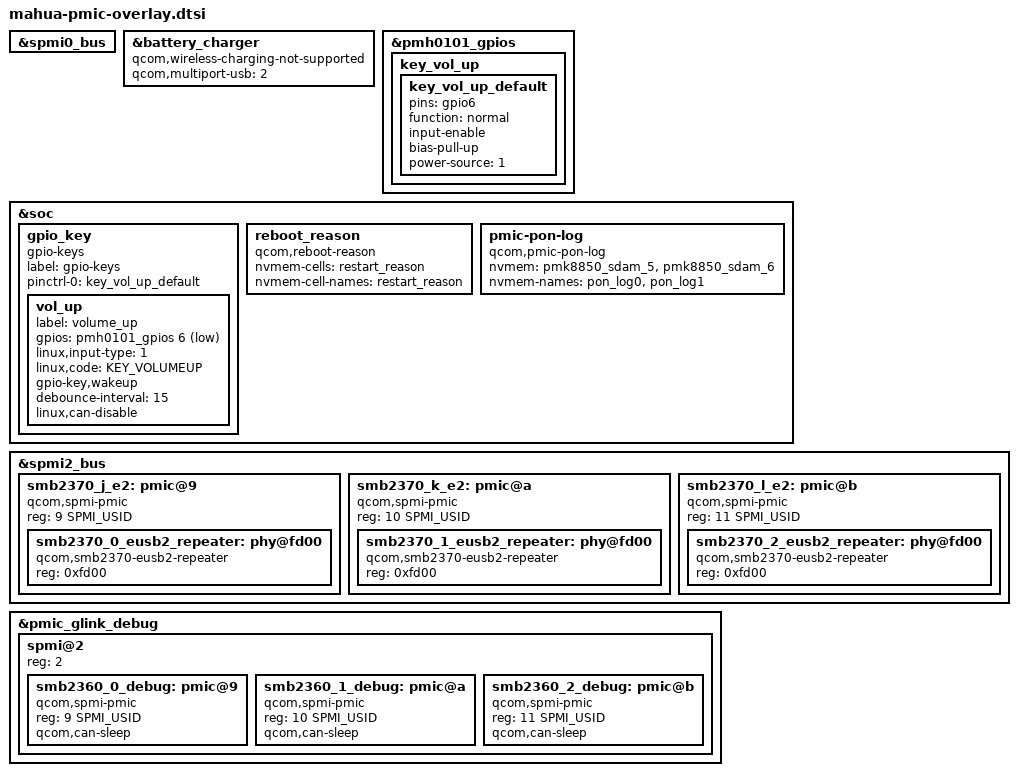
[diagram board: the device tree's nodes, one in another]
// SPDX-License-Identifier: BSD-3-Clause
/*
 * Copyright (c) Qualcomm Technologies, Inc. and/or its subsidiaries.
 */

#include <dt-bindings/gpio/gpio.h>
#include <dt-bindings/input/input.h>
#include <dt-bindings/input/linux-event-codes.h>
#include <dt-bindings/interrupt-controller/irq.h>
#include <dt-bindings/spmi/spmi.h>

#include "pmcx0102-mahua.dtsi"
#include "pmh0110-mahua.dtsi"
#include "pmh0104-mahua.dtsi"

&spmi0_bus {
	#include "pmk8850.dtsi"
	#include "pmh0101.dtsi"
};

&battery_charger {
	qcom,wireless-charging-not-supported;
	qcom,multiport-usb = <2>;
};

&pmh0101_gpios {
	key_vol_up {
		key_vol_up_default: key_vol_up_default {
			pins = "gpio6";
			function = "normal";
			input-enable;
			bias-pull-up;
			power-source = <1>;
		};
	};
};

&soc {
	gpio_key {
		compatible = "gpio-keys";
		label = "gpio-keys";
		pinctrl-names = "default";
		pinctrl-0 = <&key_vol_up_default>;
		vol_up {
			label = "volume_up";
			gpios = <&pmh0101_gpios 6 GPIO_ACTIVE_LOW>;
			linux,input-type = <1>;
			linux,code = <KEY_VOLUMEUP>;
			gpio-key,wakeup;
			debounce-interval = <15>;
			linux,can-disable;
		};
	};

	reboot_reason {
		compatible = "qcom,reboot-reason";
		nvmem-cells = <&restart_reason>;
		nvmem-cell-names = "restart_reason";
	};

	pmic-pon-log {
		compatible = "qcom,pmic-pon-log";
		nvmem = <&pmk8850_sdam_5>, <&pmk8850_sdam_6>;
		nvmem-names = "pon_log0", "pon_log1";
	};
};

&spmi2_bus {
	smb2370_j_e2: pmic@9 {
		compatible = "qcom,spmi-pmic";
		reg = <9 SPMI_USID>;
		#address-cells = <1>;
		#size-cells = <0>;

		smb2370_0_eusb2_repeater: phy@fd00 {
			compatible = "qcom,smb2370-eusb2-repeater";
			reg = <0xfd00>;
			#phy-cells = <0>;
		};
	};

	smb2370_k_e2: pmic@a {
		compatible = "qcom,spmi-pmic";
		reg = <10 SPMI_USID>;
		#address-cells = <1>;
		#size-cells = <0>;

		smb2370_1_eusb2_repeater: phy@fd00 {
			compatible = "qcom,smb2370-eusb2-repeater";
			reg = <0xfd00>;
			#phy-cells = <0>;
		};
	};

	smb2370_l_e2: pmic@b {
		compatible = "qcom,spmi-pmic";
		reg = <11 SPMI_USID>;
		#address-cells = <1>;
		#size-cells = <0>;

		smb2370_2_eusb2_repeater: phy@fd00 {
			compatible = "qcom,smb2370-eusb2-repeater";
			reg = <0xfd00>;
			#phy-cells = <0>;
		};
	};
};

&pmic_glink_debug {
	spmi@2 {
		reg = <2>;
		#address-cells = <2>;
		#size-cells = <0>;

		smb2360_0_debug: pmic@9 {
			compatible = "qcom,spmi-pmic";
			reg = <9 SPMI_USID>;
			qcom,can-sleep;
		};

		smb2360_1_debug: pmic@a {
			compatible = "qcom,spmi-pmic";
			reg = <10 SPMI_USID>;
			qcom,can-sleep;
		};

		smb2360_2_debug: pmic@b {
			compatible = "qcom,spmi-pmic";
			reg = <11 SPMI_USID>;
			qcom,can-sleep;
		};

	};
};
